# ESP32-S31 register map
Vendor: ESPRESSIF SYSTEMS (SHANGHAI) CO., LTD.; Series: ESP32 S-Series; File version: 1
CPU: RV32IMAFC r0p0, little endian, no MPU, FPU, 0 interrupt priority bits
Address unit: 32 bits
Registers are 32-bit, read-write, reset 0x0 unless marked. A register's access mark holds for its fields unless they carry their own. Offsets are from the block's base; [hi:lo] are bit positions; {n}, {i} and the like mark numbered series.

## LP_MAILBOX
Base 0x20817000
{0x0+4i} MASSEGE{i} (i=0..15)
  [31:0] MASSEGE
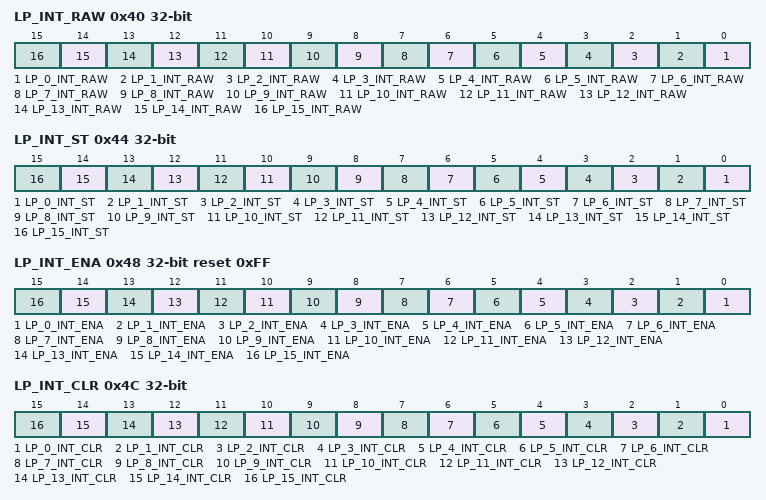
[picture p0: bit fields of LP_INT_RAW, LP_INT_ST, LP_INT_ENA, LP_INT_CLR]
0x40 LP_INT_RAW ro
  [n] LP_{n}_INT_RAW (n=0..15)
0x44 LP_INT_ST ro
  [n] LP_{n}_INT_ST (n=0..15)
0x48 LP_INT_ENA reset 0xFF
  [n] LP_{n}_INT_ENA (n=0..15)
0x4C LP_INT_CLR wo
  [n] LP_{n}_INT_CLR (n=0..15)
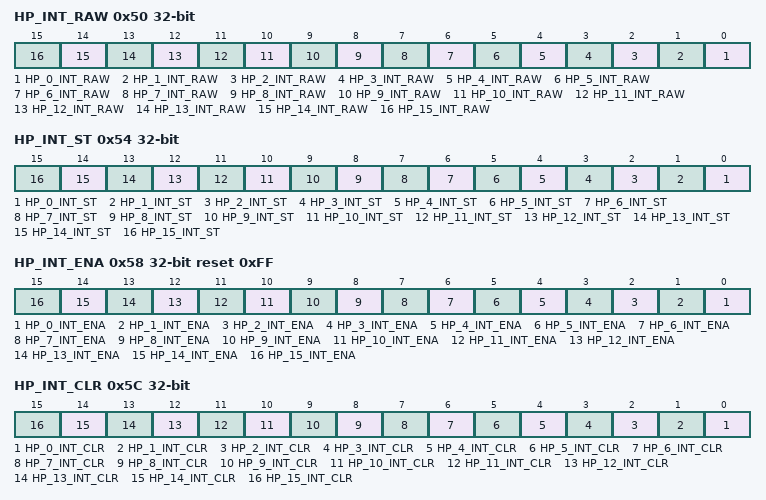
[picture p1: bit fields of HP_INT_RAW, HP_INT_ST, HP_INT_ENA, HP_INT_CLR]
0x50 HP_INT_RAW ro
  [n] HP_{n}_INT_RAW (n=0..15)
0x54 HP_INT_ST ro
  [n] HP_{n}_INT_ST (n=0..15)
0x58 HP_INT_ENA reset 0xFF
  [n] HP_{n}_INT_ENA (n=0..15)
0x5C HP_INT_CLR wo
  [n] HP_{n}_INT_CLR (n=0..15)
0x60 REG_CLK_EN
  [0] REG_CLK_EN

## TRNG — TRNG Peripheral
Base 0x20814000
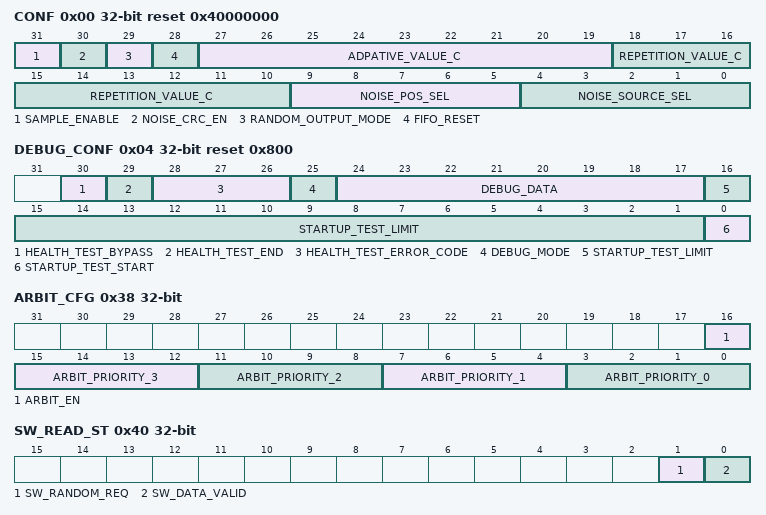
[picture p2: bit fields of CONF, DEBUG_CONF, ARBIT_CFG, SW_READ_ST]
0x00 CONF access per field reset 0x40000000 — CFG reg
  [31] SAMPLE_ENABLE rw — 1: enable rng sample loop
  [30] NOISE_CRC_EN rw — standart and nonstandart output
  [29] RANDOM_OUTPUT_MODE rw — standart and nonstandart output
  [28] FIFO_RESET wo
  [27:19] ADPATIVE_VALUE_C rw — parameter
  [18:10] REPETITION_VALUE_C rw — parameter
  [9:5] NOISE_POS_SEL rw — sel noise pos
  [4:0] NOISE_SOURCE_SEL rw — sel noise source
0x04 DEBUG_CONF access per field reset 0x800 — reserved
  [30] HEALTH_TEST_BYPASS rw
  [29] HEALTH_TEST_END wo
  [28:26] HEALTH_TEST_ERROR_CODE ro — error code
  [25] DEBUG_MODE rw — 1 for debug mode 0 for nomarl mode
  [24:17] DEBUG_DATA ro
  [16:1] STARTUP_TEST_LIMIT rw — startup limit
  [0] STARTUP_TEST_START wo — startup start
{0x8+4i} CONDITION_KEY{i} (i=0..7) — condition key reg
  [31:0] CONDITION_KEY{i} — condition key
0x28 INT_ENA — Read only register for error and done
  [0] ERROR_INT_ENA — error flag
0x2C INT_RAW — Read only register for error and done
  [0] ERROR_INT_RAW — error flag
0x30 INT_CLR wo — Read only register for error and done
  [0] ERROR_INT_CLR — error flag
0x34 INT_ST ro — Read only register for error and done
  [0] ERROR_INT_ST — error flag
0x38 ARBIT_CFG
  [16] ARBIT_EN — reg_arbit_en
  [4n+3:4n] ARBIT_PRIORITY_{n} (n=0..3) — reg_arbit_priority_{n}
0x3C SW_READ ro — sw read random reg
  [31:0] SW_RANDOM_DATA
0x40 SW_READ_ST access per field — sw read st reg
  [1] SW_RANDOM_REQ wo — sw read random req
  [0] SW_DATA_VALID ro — sw random data st
0x44 CRC_DATA ro — sw read data
  [31:0] SW_CRC_RANDOM_DATA — sw read crc random data
0x48 CRC_SYNC_DATA ro — sw read data sync
  [31:0] SW_CRC_RANDOM_DATA_SYNC — sw read crc random sync data
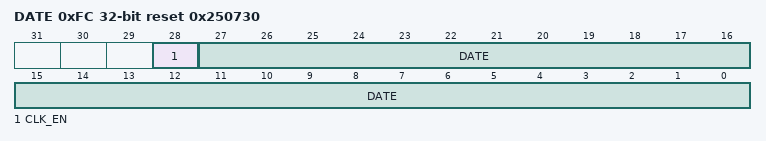
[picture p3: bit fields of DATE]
0xFC DATE reset 0x250730
  [28] CLK_EN — clock enable
  [27:0] DATE — TRNG date information

## LP_TSENS — Low-power Temperature Sensor
Base 0x20818000
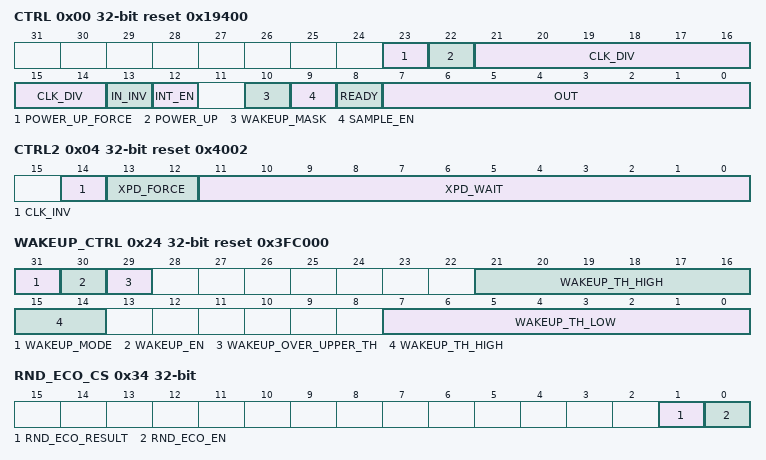
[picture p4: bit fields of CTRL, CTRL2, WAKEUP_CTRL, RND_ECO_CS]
0x00 CTRL access per field reset 0x19400 — Tsens configuration.
  [23] POWER_UP_FORCE rw — 1: dump out & power up controlled by SW, 0: by FSM.
  [22] POWER_UP rw — Temperature sensor power up.
  [21:14] CLK_DIV rw — Temperature sensor clock divider.
  [13] IN_INV rw — Invert temperature sensor data.
  [12] INT_EN rw — Enable temperature sensor to send out interrupt.
  [10] WAKEUP_MASK rw — Wake up signal mask.
  [9] SAMPLE_EN rw — Enable sample signal for wakeup module.
  [8] READY ro — Indicate temperature sensor out ready.
  [7:0] OUT ro — Temperature sensor data out.
0x04 CTRL2 reset 0x4002 — Tsens configuration.
  [14] CLK_INV, [13:12] XPD_FORCE, [11:0] XPD_WAIT
0x08 INT_RAW — Tsens interrupt raw registers.
  [0] COCPU_TSENS_WAKE_INT_RAW — Tsens wakeup interrupt raw.
0x0C INT_ST ro — Tsens interrupt status registers.
  [0] COCPU_TSENS_WAKE_INT_ST — Tsens wakeup interrupt status.
0x10 INT_ENA — Tsens interrupt enable registers.
  [0] COCPU_TSENS_WAKE_INT_ENA — Tsens wakeup interrupt enable.
0x14 INT_CLR wo — Tsens interrupt clear registers.
  [0] COCPU_TSENS_WAKE_INT_CLR — Tsens wakeup interrupt clear.
0x18 CLK_CONF — Tsens regbank configuration registers.
  [0] CLK_EN — Tsens regbank clock gating enable.
0x1C INT_ENA_W1TS wo — Tsens wakeup interrupt enable assert.
  [0] COCPU_TSENS_WAKE_INT_ENA_W1TS — Write 1 to this field to assert interrupt enable.
0x20 INT_ENA_W1TC wo — Tsens wakeup interrupt enable deassert.
  [0] COCPU_TSENS_WAKE_INT_ENA_W1TC — Write 1 to this field to deassert interrupt enable.
0x24 WAKEUP_CTRL access per field reset 0x3FC000 — Tsens wakeup control registers.
  [31] WAKEUP_MODE rw — 0:absolute value comparison mode. 1: relative value comparison mode.
  [30] WAKEUP_EN rw — Tsens wakeup enable.
  [29] WAKEUP_OVER_UPPER_TH ro — Indicates that this wakeup event arose from exceeding upper threshold.
  [21:14] WAKEUP_TH_HIGH rw — Upper threshold.
  [7:0] WAKEUP_TH_LOW rw — Lower threshold.
0x28 SAMPLE_RATE reset 0x14 — Hardware automatic sampling control registers.
  [15:0] SAMPLE_RATE — Hardware automatic sampling rate.
0x2C RND_ECO_LOW
0x30 RND_ECO_HIGH reset 0xFFFFFFFF
0x34 RND_ECO_CS access per field
  [1] RND_ECO_RESULT ro, [0] RND_ECO_EN rw
